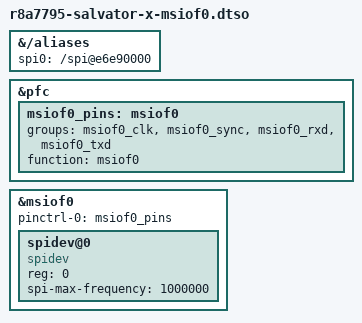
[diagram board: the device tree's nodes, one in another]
/*
 * Device Tree Overlay for MSIOF0 and spidev on r8a7795/salvator-x
 *
 * Copyright (C) 2015 Glider bvba
 *
 * This file is licensed under the terms of the GNU General Public License
 * version 2.  This program is licensed "as is" without any warranty of any
 * kind, whether express or implied.
 *
 * Pinout:
 *   - CS# = CP4
 *   - SCK = CP1
 *   - MOSI = CP2
 *   - MISO = CP3
 */

/dts-v1/ /plugin/;

/ {
	fragment-aliases {
		target-path = "/aliases";

		__overlay__ {
			/* spi0 = &msiof0; */
			spi0 = "/spi@e6e90000";
		};
	};

	fragment-pfc {
		target = <&pfc>;

		__overlay__ {
			msiof0_pins: msiof0 {
				groups = "msiof0_clk", "msiof0_sync",
					 "msiof0_rxd", "msiof0_txd";
				function = "msiof0";
			};
		};
	};

	fragment-msiof0 {
		target = <&msiof0>;

		__overlay__ {
			pinctrl-0 = <&msiof0_pins>;
			pinctrl-names = "default";

			#address-cells = <1>;
			#size-cells = <0>;
			status = "okay";

			spidev@0 {
				compatible = "spidev";
				reg = <0>;
				spi-max-frequency = <1000000>;
			};
		};
	};
};
